VERSION ""

NS_ :

BS_:

BU_: BMS Gateway

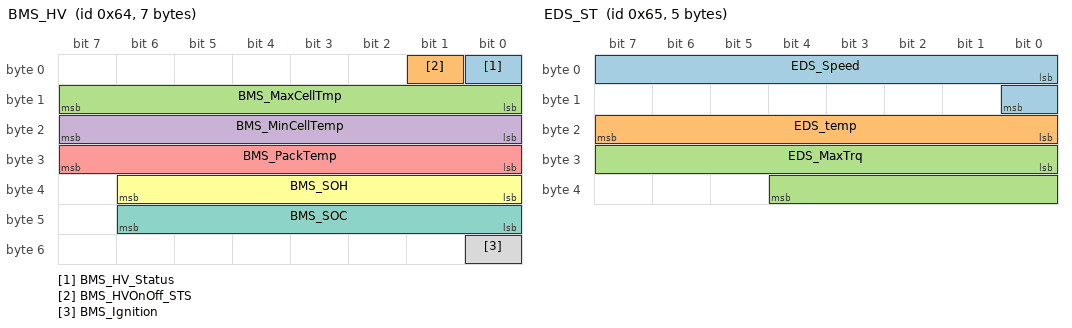
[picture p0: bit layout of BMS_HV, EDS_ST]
BO_ 100 BMS_HV: 7 BMS
 SG_ BMS_HV_Status : 0|1@1+ (1,0) [0|1] ""  Gateway
 SG_ BMS_HVOnOff_STS : 1|1@1+ (1,0) [0|1] ""  Gateway
 SG_ BMS_MaxCellTmp : 8|8@1- (1,0) [-40|120] "Celsius"  Gateway
 SG_ BMS_MinCellTemp : 16|8@1- (1,0) [-40|120] "Celsius"  Gateway
 SG_ BMS_PackTemp : 24|8@1- (1,0) [-40|120] "Celsius"  Gateway
 SG_ BMS_SOH : 32|7@1+ (1,0) [0|100] "%"  Gateway
 SG_ BMS_SOC : 40|7@1+ (1,0) [0|100] "%"  Gateway
 SG_ BMS_Ignition : 48|1@1+ (1,0) [0|1] ""  Gateway

BO_ 101 EDS_ST: 5 BMS
 SG_ EDS_Speed : 0|9@1+ (1,0) [0|400] "kmh"  Gateway
 SG_ EDS_temp : 16|8@1+ (1,0) [-40|120] "Celsius"  Gateway
 SG_ EDS_MaxTrq : 24|13@1+ (1,0) [0|5000] "Nm"  Gateway
